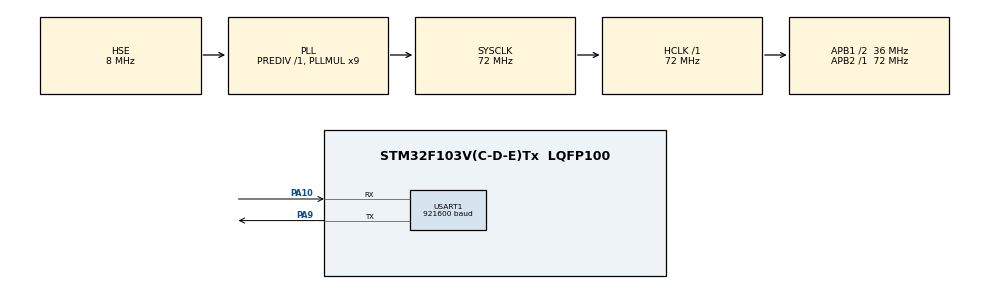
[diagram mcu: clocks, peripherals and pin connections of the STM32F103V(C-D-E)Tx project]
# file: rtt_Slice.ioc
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Mcu.Family=STM32F1
Mcu.Name=STM32F103V(C-D-E)Tx
Mcu.Package=LQFP100
NVIC.PriorityGroup=NVIC_PRIORITYGROUP_4
OSC_IN.Mode=HSE-External-Oscillator
OSC_IN.Signal=RCC_OSC_IN
OSC_OUT.Mode=HSE-External-Oscillator
OSC_OUT.Signal=RCC_OSC_OUT
PA10.Mode=Asynchronous
PA10.Signal=USART1_RX
PA9.Mode=Asynchronous
PA9.Signal=USART1_TX
ProjectManager.HeapSize=0x200
ProjectManager.StackSize=0x400
ProjectManager.TargetToolchain=MDK-ARM V5.32
RCC.AHBFreq_Value=72000000
RCC.APB1CLKDivider=RCC_HCLK_DIV2
RCC.APB1Freq_Value=36000000
RCC.APB1TimFreq_Value=72000000
RCC.APB2Freq_Value=72000000
RCC.APB2TimFreq_Value=72000000
RCC.HCLKFreq_Value=72000000
RCC.PLLMUL=RCC_PLL_MUL9
RCC.PLLSourceVirtual=RCC_PLLSOURCE_HSE
RCC.SYSCLKFreq_VALUE=72000000
RCC.SYSCLKSource=RCC_SYSCLKSOURCE_PLLCLK
RCC.USBFreq_Value=72000000
USART1.BaudRate=921600
USART1.VirtualMode=VM_ASYNC
VP_SYS_VS_ND.Mode=No_Debug
board=custom

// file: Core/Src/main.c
/* USER CODE BEGIN Header */
/**
  ******************************************************************************
  * @file           : main.c
  * @brief          : Main program body
  ******************************************************************************
  * @attention
  *
  * Copyright (c) 2023 STMicroelectronics.
  * All rights reserved.
  *
  * This software is licensed under terms that can be found in the LICENSE file
  * in the root directory of this software component.
  * If no LICENSE file comes with this software, it is provided AS-IS.
  *
  ******************************************************************************
  */
/* USER CODE END Header */
#include "main.h"
#include "usart.h"
#include "gpio.h"
#include "rtthread.h"

void SystemClock_Config(void);

static int test_print()
{
  static rt_uint8_t test_buffer[] = "test buffer";
  rt_uint8_t test_butter_buffer[50] = {0};
  rt_memset(test_butter_buffer, '1', sizeof(test_butter_buffer) - 1);
  rt_kprintf("%s  |\r\n", test_butter_buffer);

  rt_memcmp(test_buffer, test_butter_buffer, sizeof(test_buffer));
  rt_kprintf("%s  |\r\n", test_buffer);
  rt_kprintf("test_test\r\n");

  return 0;
}
INIT_BOARD_EXPORT(test_print);

typedef struct
{
  rt_list_t list_node;
  uint32_t data;
}test_list_t;

static int teset_list()
{
  test_list_t data1, data2, data3;
  rt_kprintf("teset_list\r\n");
  data1.data = 10;
  data2.data = 20;
  data3.data = 30;
  rt_list_init(&data1.list_node);
  rt_list_init(&data2.list_node);
  rt_list_init(&data3.list_node);
  rt_list_insert_after(&data1.list_node, &data2.list_node);
  rt_list_insert_after(&data1.list_node, &data3.list_node);
  rt_list_t* p;
  rt_list_for_each(p, &data2.list_node)
  {
    rt_kprintf("%d\r\n", rt_list_entry(p, test_list_t, list_node)->data);
  }
  return 0;
}
INIT_BOARD_EXPORT(teset_list);
int main(void)
{

  /* MCU Configuration--------------------------------------------------------*/

  /* Reset of all peripherals, Initializes the Flash interface and the Systick. */
  HAL_Init();

  /* Configure the system clock */
  SystemClock_Config();

  /* Initialize all configured peripherals */
  MX_GPIO_Init();
  MX_USART1_UART_Init();

  /* Infinite loop */
  /* USER CODE BEGIN WHILE */
  rt_components_board_init();
  while (1)
  {
    /* USER CODE END WHILE */

  }
}

void SystemClock_Config(void)
{
  RCC_OscInitTypeDef RCC_OscInitStruct = {0};
  RCC_ClkInitTypeDef RCC_ClkInitStruct = {0};

  /** Initializes the RCC Oscillators according to the specified parameters
  * in the RCC_OscInitTypeDef structure.
  */
  RCC_OscInitStruct.OscillatorType = RCC_OSCILLATORTYPE_HSE;
  RCC_OscInitStruct.HSEState = RCC_HSE_ON;
  RCC_OscInitStruct.HSEPredivValue = RCC_HSE_PREDIV_DIV1;
  RCC_OscInitStruct.HSIState = RCC_HSI_ON;
  RCC_OscInitStruct.PLL.PLLState = RCC_PLL_ON;
  RCC_OscInitStruct.PLL.PLLSource = RCC_PLLSOURCE_HSE;
  RCC_OscInitStruct.PLL.PLLMUL = RCC_PLL_MUL9;
  if (HAL_RCC_OscConfig(&RCC_OscInitStruct) != HAL_OK)
  {
    Error_Handler();
  }

  /** Initializes the CPU, AHB and APB buses clocks
  */
  RCC_ClkInitStruct.ClockType = RCC_CLOCKTYPE_HCLK|RCC_CLOCKTYPE_SYSCLK
                              |RCC_CLOCKTYPE_PCLK1|RCC_CLOCKTYPE_PCLK2;
  RCC_ClkInitStruct.SYSCLKSource = RCC_SYSCLKSOURCE_PLLCLK;
  RCC_ClkInitStruct.AHBCLKDivider = RCC_SYSCLK_DIV1;
  RCC_ClkInitStruct.APB1CLKDivider = RCC_HCLK_DIV2;
  RCC_ClkInitStruct.APB2CLKDivider = RCC_HCLK_DIV1;

  if (HAL_RCC_ClockConfig(&RCC_ClkInitStruct, FLASH_LATENCY_2) != HAL_OK)
  {
    Error_Handler();
  }
}

void Error_Handler(void)
{
  __disable_irq();
  while (1)
  {
  }
}
